VERSION ""

VERSION ""

NS_ :

BS_:

BU_: Vector__XXX

BA_DEF_ BO_  "VFrameFormat" ENUM  "StandardCAN","ExtendedCAN";
BA_DEF_DEF_ "VFrameFormat" "StandardCAN";

CM_ "Ioniq 6 (2023+, ccNC) frame ids. The ccNC cars re-address classic 11-bit car-bus frames onto 29-bit extended ids that encode the original 11-bit id:";
CM_ "    prefix = 4 * (base >> 4)";
CM_ "    ext    = (prefix << 20) | (base << 8) | index        (id11 = base + index)";
CM_ "base = min(11-bit id of the family) - 1 and index = 1..N inside the family. Decode with base = (ext >> 8) & 0xFFF, index = ext & 0xFF, id11 = base + index.";
CM_ "This file uses BO_ = 0x80000000 | ext for the extended frames, plus BA_ \"VFrameFormat\" BO_ <id> 1 (ExtendedCAN). Worked example: 0x2AD -> base 0x2AA, index 3 -> 0x0A82AA03 -> BO_ 2323819011.";
CM_ "The remap is PARTIAL. Frames that keep their 11-bit id on Ioniq 6 include 0x448 (car bus) and the head-unit set 0x0C7 / 0x4CC / 0x4E8 / 0x4ED / 0x651 / 0x652.";
CM_ "Verified byte-for-byte against Ioniq 5 / EV6 logs: 0x037 -> 0x00C03502, 0x038 -> 0x00C03503, 0x0A2 -> 0x0280A002, 0x10C -> 0x04010A02, 0x2AC/0x2AD/0x2AE -> 0x0A82AA02/03/04, 0x2E2/0x2E3/0x2E4 -> 0x0B82E002/03/04, 0x397/0x398 -> 0x0E439502/03.";
CM_ "DERIVED, NOT YET OBSERVED ON THE WIRE: 0x152 -> 0x05415002 (BO_ 2235650050). Prefix table and full mapping: ../egmpdbc/README.md.";

BO_ 56 Power_Status: 8 Vector__XXX
	SG_ Power_Status_Ready : 0|4@1+ (1,0) [0|0] "" Vector__XXX

CM_ BO_ 56 "POWER_STATUS (0x038) power/READY frame, Ioniq 5 / EV6 form. LS nibble of byte 0: 0x01 = awake but off (with some lag), 0x04 = READY. On Ioniq 6 the frame is the 29-bit 0x00C03503 = BO_ 2160080131.";
CM_ SG_ 56 Power_Status_Ready "LS nibble of byte 0";

VAL_ 56 Power_Status_Ready 1 "Awake_Not_Ready" 4 "Ready" ;

BO_ 2160080131 Power_Status_Ioniq6: 8 Vector__XXX
	SG_ Power_Status_Ready : 0|4@1+ (1,0) [0|0] "" Vector__XXX

CM_ BO_ 2160080131 "POWER_STATUS for Ioniq 6: 29-bit 0x00C03503, the ccNC remap of 11-bit 0x038 (family 0x036-0x039, base 0x035, index 3). LS nibble of byte 0: 0x01 = awake but off, 0x04 = READY. Observed as 01 00 00 00 00 00 06 00 (awake, not READY) throughout an Ioniq 6 capture.";
CM_ SG_ 2160080131 Power_Status_Ready "LS nibble of byte 0";

VAL_ 2160080131 Power_Status_Ready 1 "Awake_Not_Ready" 4 "Ready" ;

BO_ 199 Toggle_Battery_Preconditioning: 8 Vector__XXX
	SG_ Battery_Preconditioning_0 : 24|8@1+ (1,0) [0|0] "" Vector__XXX
	SG_ Battery_Preconditioning_1 : 32|8@1+ (1,0) [0|0] "" Vector__XXX

CM_ BO_ 199 "Low level BMU control (preconditioning, utility mode activation; involved in start/stop). Head-unit bus frame, so the car-bus remap does not apply and the 11-bit id stands on Ioniq 6; absent from the Ioniq 6 capture on disk (command frame).";
CM_ SG_ 199 Battery_Preconditioning_0 "byte 3";
CM_ SG_ 199 Battery_Preconditioning_1 "byte 4";

VAL_ 199 Battery_Preconditioning_0 0 "Off" 64 "On" ;
VAL_ 199 Battery_Preconditioning_1 0 "Off" 3 "On" ;

BO_ 685 BMS_Precond_Status: 8 Vector__XXX
	SG_ Battery_Precond_State : 8|8@1+ (1,0) [0|0] "" Vector__XXX

CM_ BO_ 685 "BMS_Precond_Status (0x2AD), Ioniq 5 / EV6. Byte 1 state: Ioniq 5 0x01 idle / 0x05 starting / 0x15 started; EV6 0x41 / 0x45 / 0x55. Ioniq 6 uses the 29-bit remap 0x0A82AA03 = BO_ 2323819011 (family 0x2AB-0x2AE, base 0x2AA, index 3) instead.";
CM_ SG_ 685 Battery_Precond_State "byte 1 state";

VAL_ 685 Battery_Precond_State 1 "Off" 5 "Preparing" 21 "On" ;

BO_ 2323819011 BMS_Precond_Status_Ioniq6: 8 Vector__XXX
	SG_ Battery_Precond_State : 8|8@1+ (1,0) [0|0] "" Vector__XXX

CM_ BO_ 2323819011 "BMS_Precond_Status for Ioniq 6 (extended ID 0x0A82AA03 = ccNC remap of 11-bit 0x2AD). Same byte-1 state semantics as 0x2AD on Ioniq 5 / EV6. Payload verified byte-for-byte against an Ioniq 5 capture: 00 01 00 40 FF FF FF 0F.";
CM_ SG_ 2323819011 Battery_Precond_State "byte 1 state";

VAL_ 2323819011 Battery_Precond_State 1 "Off" 5 "Preparing" 21 "On" ;

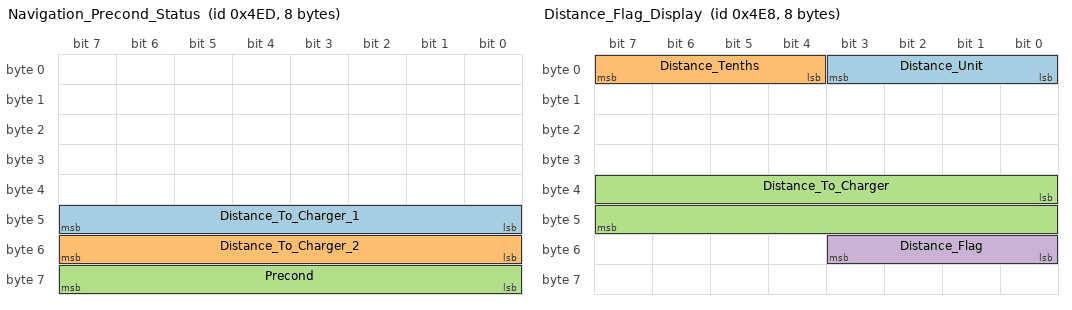
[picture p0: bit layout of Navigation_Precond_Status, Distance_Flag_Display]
BO_ 1261 Navigation_Precond_Status: 8 Vector__XXX
	SG_ Distance_To_Charger_1 : 40|8@1+ (1,0) [0|0] "" Vector__XXX
	SG_ Distance_To_Charger_2 : 48|8@1+ (1,0) [0|0] "" Vector__XXX
	SG_ Precond : 56|8@1+ (1,0) [0|0] "" Vector__XXX

CM_ BO_ 1261 "Navigation_Precond_Status (0x4ED): navigation distance to charger and precondition flag. Head-unit bus frame, kept 11-bit on Ioniq 6 (present in the Ioniq 6 capture as 00 00 00 00 00 FF FF 1F).";
CM_ SG_ 1261 Distance_To_Charger_1 "byte 5";
CM_ SG_ 1261 Distance_To_Charger_2 "byte 6";
CM_ SG_ 1261 Precond "byte 7";

BO_ 1256 Distance_Flag_Display: 8 Vector__XXX
	SG_ Distance_Unit : 0|4@1+ (1,0) [0|0] "" Vector__XXX
	SG_ Distance_Tenths : 4|4@1+ (1,0) [0|0] "" Vector__XXX
	SG_ Distance_To_Charger : 32|16@1+ (1,0) [0|0] "" Vector__XXX
	SG_ Distance_Flag : 48|4@1+ (1,0) [0|0] "" Vector__XXX

CM_ BO_ 1256 "Distance/flag display (0x4E8): byte0 = tenths<<4 | unit; bytes 4-5 = uint16 distance (LE); byte 6 LS nibble = flag. 0xFFFF distance hides the number. Head-unit bus frame, kept 11-bit on Ioniq 6.";
CM_ SG_ 1256 Distance_Unit "byte 0 LS nibble";
CM_ SG_ 1256 Distance_Tenths "byte 0 MS nibble";
CM_ SG_ 1256 Distance_To_Charger "bytes 4-5, uint16 LE";
CM_ SG_ 1256 Distance_Flag "byte 6 LS nibble";

VAL_ 1256 Distance_Unit 0 "M" 1 "KM" 2 "MI" 3 "FT" 4 "YD" ;
VAL_ 1256 Distance_Flag 0 "Destination" 1 "Blue 1" 2 "Blue 2" 3 "Blue 3" 4 "Blue 4" 15 "None" ;

BO_ 1228 Precond_Countdown_Flag: 8 Vector__XXX
	SG_ Precond_Countdown : 0|8@1+ (1,0) [0|0] "" Vector__XXX

CM_ BO_ 1228 "Preconditioning countdown flag (0x4CC). Head-unit bus frame, kept 11-bit on Ioniq 6 (present in the Ioniq 6 capture as 08 00 00 24 00 00 03 00).";
CM_ SG_ 1228 Precond_Countdown "byte 0";

BO_ 338 Battery_Temperature: 8 Vector__XXX
	SG_ Battery_Temperature_Min : 0|8@1- (1,0) [0|0] "" Vector__XXX
	SG_ Battery_Temperature_Max : 8|8@1- (1,0) [0|0] "" Vector__XXX

CM_ BO_ 338 "Battery temperature (0x152), Ioniq 5 / EV6 form: data[0] = min cell temp, data[1] = max cell temp (int8, deg C). On Ioniq 6 the frame is the 29-bit 0x05415002 = BO_ 2235650050, NOT this 11-bit id.";
CM_ SG_ 338 Battery_Temperature_Min "byte 0, signed deg C";
CM_ SG_ 338 Battery_Temperature_Max "byte 1, signed deg C";

BO_ 2235650050 Battery_Temperature_Ioniq6: 8 Vector__XXX
	SG_ Battery_Temperature_Min : 0|8@1- (1,0) [0|0] "" Vector__XXX
	SG_ Battery_Temperature_Max : 8|8@1- (1,0) [0|0] "" Vector__XXX

CM_ BO_ 2235650050 "Battery temperature for Ioniq 6: 29-bit 0x05415002, the ccNC remap of 11-bit 0x152 / BMS_10_100ms_2 (family 0x151-0x154, base 0x150, index 2). data[0] = min cell temp, data[1] = max cell temp (int8, deg C). DERIVED FROM THE ID SCHEME, NOT YET OBSERVED ON THE WIRE: the whole 0x150 family is absent from the only Ioniq 6 capture on disk, so confirm this id against a capture taken with the car in READY.";
CM_ SG_ 2235650050 Battery_Temperature_Min "byte 0, signed deg C";
CM_ SG_ 2235650050 Battery_Temperature_Max "byte 1, signed deg C";

BO_ 1096 Steering_Wheel_Buttons: 8 Vector__XXX
	SG_ Steering_Wheel_Other_Button : 16|8@1+ (1,0) [0|0] "" Vector__XXX
	SG_ Steering_Wheel_Star_Button : 40|8@1+ (1,0) [0|0] "" Vector__XXX

CM_ BO_ 1096 "Steering-wheel buttons (0x448): star, mode, speak, call, volume, skip, OK buttons. Car-bus frame that nevertheless KEEPS its 11-bit id on Ioniq 6 (present in the Ioniq 6 capture as 7F 00 00 00 00 00 00 00), so the ccNC remap is only partial.";
CM_ SG_ 1096 Steering_Wheel_Other_Button "byte 2";
CM_ SG_ 1096 Steering_Wheel_Star_Button "byte 5";

VAL_ 1096 Steering_Wheel_Other_Button 0 "None_Pressed" 1 "Speak_Pressed" 4 "Phone_Pressed" 64 "Mode_Pressed" ;
VAL_ 1096 Steering_Wheel_Star_Button 0 "Not_Pressed" 16 "Pressed" ;

BO_ 1617 AVN_Buttons_651: 8 Vector__XXX
	SG_ AVN_Vol_In : 12|4@1+ (1,0) [0|0] "" Vector__XXX
	SG_ AVN_Tuner_In : 28|4@1+ (1,0) [0|0] "" Vector__XXX

CM_ BO_ 1617 "AVN (head unit) button events (0x651); event frames sent only on press/release. VOL_IN = byte 1 MS nibble, TUNER_IN = byte 3 MS nibble. Head-unit bus frame, kept 11-bit on Ioniq 6.";
CM_ SG_ 1617 AVN_Vol_In "byte 1 MS nibble (mask 0xF0)";
CM_ SG_ 1617 AVN_Tuner_In "byte 3 MS nibble (mask 0xF0)";

VAL_ 1617 AVN_Vol_In 0 "Release" 3 "Release" 4 "Press" 7 "Press" ;
VAL_ 1617 AVN_Tuner_In 0 "Release" 3 "Release" 4 "Press" 7 "Press" ;

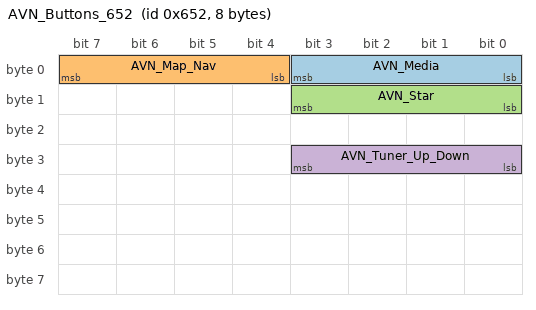
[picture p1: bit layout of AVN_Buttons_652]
BO_ 1618 AVN_Buttons_652: 8 Vector__XXX
	SG_ AVN_Media : 0|4@1+ (1,0) [0|0] "" Vector__XXX
	SG_ AVN_Map_Nav : 4|4@1+ (1,0) [0|0] "" Vector__XXX
	SG_ AVN_Star : 8|4@1+ (1,0) [0|0] "" Vector__XXX
	SG_ AVN_Tuner_Up_Down : 24|4@1+ (1,0) [0|0] "" Vector__XXX

CM_ BO_ 1618 "AVN (head unit) button events (0x652). Per-byte nibble encoding: D1(byte0) MS=MAP/NAV LS=MEDIA; D2(byte1) LS=STAR; D4(byte3) LS=TUNER UP/DOWN. Seek/Call/Home/Mode signals are EV6-specific (see fluxer notes). Head-unit bus frame, kept 11-bit on Ioniq 6.";
CM_ SG_ 1618 AVN_Media "byte 0 LS nibble (mask 0x0F). 1=Media, 4=Radio (start radio, unconfirmed per fluxer notes)";
CM_ SG_ 1618 AVN_Map_Nav "byte 0 MS nibble (mask 0xF0). 1=Nav, 4=Map";
CM_ SG_ 1618 AVN_Star "byte 1 LS nibble (mask 0x0F). 4=Star";
CM_ SG_ 1618 AVN_Tuner_Up_Down "byte 3 LS nibble (mask 0x0F). 1=Down, 4=Up";

VAL_ 1618 AVN_Media 0 "Release" 1 "Press" 4 "Radio" 12 "Release" 13 "Press" ;
VAL_ 1618 AVN_Map_Nav 0 "Release" 1 "Nav Press" 3 "Release" 4 "Map Press" 7 "Map Press" 12 "Release" 13 "Nav Press" ;
VAL_ 1618 AVN_Star 0 "Release" 3 "Release" 4 "Press" 7 "Press" ;
VAL_ 1618 AVN_Tuner_Up_Down 0 "Release" 1 "Down Press" 3 "Release" 4 "Up Press" 7 "Up Press" 12 "Release" 13 "Down Press" ;

BA_ "VFrameFormat" BO_ 2160080131 1;
BA_ "VFrameFormat" BO_ 2235650050 1;
BA_ "VFrameFormat" BO_ 2323819011 1;
